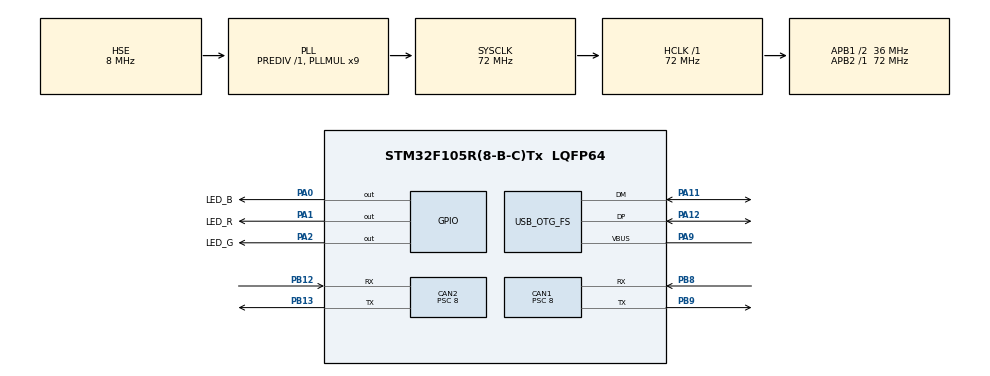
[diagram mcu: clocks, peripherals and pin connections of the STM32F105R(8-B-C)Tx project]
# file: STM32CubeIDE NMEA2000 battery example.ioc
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CAN1.BS1=CAN_BS1_15TQ
CAN1.BS2=CAN_BS2_2TQ
CAN1.CalculateBaudRate=250000
CAN1.CalculateTimeBit=4000
CAN1.CalculateTimeQuantum=222.22222222222223
CAN1.Mode=CAN_MODE_NORMAL
CAN1.Prescaler=8
CAN2.BS1=CAN_BS1_15TQ
CAN2.BS2=CAN_BS2_2TQ
CAN2.CalculateBaudRate=250000
CAN2.CalculateTimeBit=4000
CAN2.CalculateTimeQuantum=222.22222222222223
CAN2.Prescaler=8
Mcu.Family=STM32F1
Mcu.Name=STM32F105R(8-B-C)Tx
Mcu.Package=LQFP64
NVIC.CAN1_RX0_IRQn=true\:0\:0\:false\:false\:true\:true\:true\:true
NVIC.CAN1_TX_IRQn=true\:0\:0\:false\:false\:true\:true\:true\:true
NVIC.CAN2_RX1_IRQn=true\:0\:0\:false\:false\:true\:true\:true\:true
NVIC.CAN2_TX_IRQn=true\:0\:0\:false\:false\:true\:true\:true\:true
NVIC.OTG_FS_IRQn=true\:0\:0\:false\:false\:true\:true\:true\:true
NVIC.PriorityGroup=NVIC_PRIORITYGROUP_4
NVIC.TIM2_IRQn=true\:0\:0\:false\:false\:true\:true\:true\:true
PA0-WKUP.GPIO_Label=LED_B
PA0-WKUP.Signal=GPIO_Output
PA1.GPIO_Label=LED_R
PA1.Signal=GPIO_Output
PA11.Mode=Device_Only
PA11.Signal=USB_OTG_FS_DM
PA12.Mode=Device_Only
PA12.Signal=USB_OTG_FS_DP
PA13.Mode=Trace_Asynchronous_SW
PA13.Signal=SYS_JTMS-SWDIO
PA14.Mode=Trace_Asynchronous_SW
PA14.Signal=SYS_JTCK-SWCLK
PA2.GPIO_Label=LED_G
PA2.Signal=GPIO_Output
PA9.Mode=Activate_VBUS
PA9.Signal=USB_OTG_FS_VBUS
PB12.Mode=CAN_Activate
PB12.Signal=CAN2_RX
PB13.Mode=CAN_Activate
PB13.Signal=CAN2_TX
PB3.Mode=Trace_Asynchronous_SW
PB3.Signal=SYS_TRACESWO
PB8.Mode=CAN_Activate
PB8.Signal=CAN1_RX
PB9.Mode=CAN_Activate
PB9.Signal=CAN1_TX
PD0-OSC_IN.Mode=HSE-External-Oscillator
PD0-OSC_IN.Signal=RCC_OSC_IN
PD1-OSC_OUT.Mode=HSE-External-Oscillator
PD1-OSC_OUT.Signal=RCC_OSC_OUT
ProjectManager.HeapSize=0x200
ProjectManager.StackSize=0x400
ProjectManager.TargetToolchain=STM32CubeIDE
RCC.ADCPresc=RCC_ADCPCLK2_DIV6
RCC.AHBFreq_Value=72000000
RCC.APB1CLKDivider=RCC_HCLK_DIV2
RCC.APB1Freq_Value=36000000
RCC.APB1TimFreq_Value=72000000
RCC.APB2Freq_Value=72000000
RCC.APB2TimFreq_Value=72000000
RCC.HCLKFreq_Value=72000000
RCC.PLLMUL=RCC_PLL_MUL9
RCC.PLLSourceVirtual=RCC_PLLSOURCE_HSE
RCC.SYSCLKFreq_VALUE=72000000
RCC.SYSCLKSource=RCC_SYSCLKSOURCE_PLLCLK
RCC.USBFreq_Value=48000000
TIM2.Period=1000-1
TIM2.Prescaler=72-1
TIM2.TIM_MasterOutputTrigger=TIM_TRGO_UPDATE
TIM2.TIM_MasterSlaveMode=TIM_MASTERSLAVEMODE_ENABLE
TIM5.AutoReloadPreload=TIM_AUTORELOAD_PRELOAD_ENABLE
TIM5.Period=720-1
USB_DEVICE.CLASS_NAME_FS=CDC
USB_DEVICE.VirtualMode=Cdc
USB_DEVICE.VirtualModeFS=Cdc_FS
USB_OTG_FS.VirtualMode=Device_Only
VP_TIM2_VS_ClockSourceINT.Mode=Internal
VP_TIM5_VS_ClockSourceINT.Mode=Internal
VP_USB_DEVICE_VS_USB_DEVICE_CDC_FS.Mode=CDC_FS
board=custom

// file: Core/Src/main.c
/* USER CODE BEGIN Header */
/**
  ******************************************************************************
  * @file           : main.c
  * @brief          : Main program body
  ******************************************************************************
  * @attention
  *
  * <h2><center>&copy; Copyright (c) 2022 STMicroelectronics.
  * All rights reserved.</center></h2>
  *
  * This software component is licensed by ST under BSD 3-Clause license,
  * the "License"; You may not use this file except in compliance with the
  * License. You may obtain a copy of the License at:
  *                        opensource.org/licenses/BSD-3-Clause
  *
  ******************************************************************************
  */
/* USER CODE END Header */
#include "main.h"
#include "usb_device.h"

/* USER CODE BEGIN Includes */
#include "cpp_link.hpp"
/* USER CODE END Includes */

CAN_HandleTypeDef hcan1;
CAN_HandleTypeDef hcan2;

TIM_HandleTypeDef htim2;
TIM_HandleTypeDef htim5;

void SystemClock_Config(void);
static void MX_GPIO_Init(void);
static void MX_CAN1_Init(void);
static void MX_CAN2_Init(void);
static void MX_TIM2_Init(void);
static void MX_TIM5_Init(void);

int main(void)
{

  /* MCU Configuration--------------------------------------------------------*/

  /* Reset of all peripherals, Initializes the Flash interface and the Systick. */
  HAL_Init();

  /* Configure the system clock */
  SystemClock_Config();

  /* Initialize all configured peripherals */
  /* Initialize all configured peripherals */
  MX_GPIO_Init();
  MX_CAN1_Init();
  MX_CAN2_Init();
  MX_TIM2_Init();
  MX_USB_DEVICE_Init();
  MX_TIM5_Init();

  /* Infinite loop */
  /* USER CODE BEGIN WHILE */
  cpp_link();
  // we never exit cpp_link()!!!!
  // while (1) should be empty

  while (1)
  {

    /* USER CODE END WHILE */

  }
}

void SystemClock_Config(void)
{
  RCC_OscInitTypeDef RCC_OscInitStruct = {0};
  RCC_ClkInitTypeDef RCC_ClkInitStruct = {0};
  RCC_PeriphCLKInitTypeDef PeriphClkInit = {0};

  /** Initializes the RCC Oscillators according to the specified parameters
  * in the RCC_OscInitTypeDef structure.
  */
  RCC_OscInitStruct.OscillatorType = RCC_OSCILLATORTYPE_HSE;
  RCC_OscInitStruct.HSEState = RCC_HSE_ON;
  RCC_OscInitStruct.HSEPredivValue = RCC_HSE_PREDIV_DIV1;
  RCC_OscInitStruct.HSIState = RCC_HSI_ON;
  RCC_OscInitStruct.Prediv1Source = RCC_PREDIV1_SOURCE_HSE;
  RCC_OscInitStruct.PLL.PLLState = RCC_PLL_ON;
  RCC_OscInitStruct.PLL.PLLSource = RCC_PLLSOURCE_HSE;
  RCC_OscInitStruct.PLL.PLLMUL = RCC_PLL_MUL9;
  RCC_OscInitStruct.PLL2.PLL2State = RCC_PLL_NONE;
  if (HAL_RCC_OscConfig(&RCC_OscInitStruct) != HAL_OK)
  {
    Error_Handler();
  }

  /** Initializes the CPU, AHB and APB buses clocks
  */
  RCC_ClkInitStruct.ClockType = RCC_CLOCKTYPE_HCLK|RCC_CLOCKTYPE_SYSCLK
                              |RCC_CLOCKTYPE_PCLK1|RCC_CLOCKTYPE_PCLK2;
  RCC_ClkInitStruct.SYSCLKSource = RCC_SYSCLKSOURCE_PLLCLK;
  RCC_ClkInitStruct.AHBCLKDivider = RCC_SYSCLK_DIV1;
  RCC_ClkInitStruct.APB1CLKDivider = RCC_HCLK_DIV2;
  RCC_ClkInitStruct.APB2CLKDivider = RCC_HCLK_DIV1;

  if (HAL_RCC_ClockConfig(&RCC_ClkInitStruct, FLASH_LATENCY_2) != HAL_OK)
  {
    Error_Handler();
  }
  PeriphClkInit.PeriphClockSelection = RCC_PERIPHCLK_USB;
  PeriphClkInit.UsbClockSelection = RCC_USBCLKSOURCE_PLL_DIV3;
  if (HAL_RCCEx_PeriphCLKConfig(&PeriphClkInit) != HAL_OK)
  {
    Error_Handler();
  }

  /** Configure the Systick interrupt time
  */
  __HAL_RCC_PLLI2S_ENABLE();
}

static void MX_CAN1_Init(void)
{

  hcan1.Instance = CAN1;
  hcan1.Init.Prescaler = 8;
  hcan1.Init.Mode = CAN_MODE_NORMAL;
  hcan1.Init.SyncJumpWidth = CAN_SJW_1TQ;
  hcan1.Init.TimeSeg1 = CAN_BS1_15TQ;
  hcan1.Init.TimeSeg2 = CAN_BS2_2TQ;
  hcan1.Init.TimeTriggeredMode = DISABLE;
  hcan1.Init.AutoBusOff = DISABLE;
  hcan1.Init.AutoWakeUp = DISABLE;
  hcan1.Init.AutoRetransmission = DISABLE;
  hcan1.Init.ReceiveFifoLocked = DISABLE;
  hcan1.Init.TransmitFifoPriority = DISABLE;
  if (HAL_CAN_Init(&hcan1) != HAL_OK)
  {
    Error_Handler();
  }

}

static void MX_CAN2_Init(void)
{

  hcan2.Instance = CAN2;
  hcan2.Init.Prescaler = 4;
  hcan2.Init.Mode = CAN_MODE_NORMAL;
  hcan2.Init.SyncJumpWidth = CAN_SJW_1TQ;
  hcan2.Init.TimeSeg1 = CAN_BS1_15TQ;
  hcan2.Init.TimeSeg2 = CAN_BS2_2TQ;
  hcan2.Init.TimeTriggeredMode = DISABLE;
  hcan2.Init.AutoBusOff = DISABLE;
  hcan2.Init.AutoWakeUp = DISABLE;
  hcan2.Init.AutoRetransmission = DISABLE;
  hcan2.Init.ReceiveFifoLocked = DISABLE;
  hcan2.Init.TransmitFifoPriority = DISABLE;
  if (HAL_CAN_Init(&hcan2) != HAL_OK)
  {
    Error_Handler();
  }

}

static void MX_TIM2_Init(void)
{

  TIM_ClockConfigTypeDef sClockSourceConfig = {0};
  TIM_MasterConfigTypeDef sMasterConfig = {0};

  htim2.Instance = TIM2;
  htim2.Init.Prescaler = 72-1;
  htim2.Init.CounterMode = TIM_COUNTERMODE_UP;
  htim2.Init.Period = 1000-1;
  htim2.Init.ClockDivision = TIM_CLOCKDIVISION_DIV1;
  htim2.Init.AutoReloadPreload = TIM_AUTORELOAD_PRELOAD_DISABLE;
  if (HAL_TIM_Base_Init(&htim2) != HAL_OK)
  {
    Error_Handler();
  }
  sClockSourceConfig.ClockSource = TIM_CLOCKSOURCE_INTERNAL;
  if (HAL_TIM_ConfigClockSource(&htim2, &sClockSourceConfig) != HAL_OK)
  {
    Error_Handler();
  }
  sMasterConfig.MasterOutputTrigger = TIM_TRGO_UPDATE;
  sMasterConfig.MasterSlaveMode = TIM_MASTERSLAVEMODE_ENABLE;
  if (HAL_TIMEx_MasterConfigSynchronization(&htim2, &sMasterConfig) != HAL_OK)
  {
    Error_Handler();
  }

}

static void MX_TIM5_Init(void)
{

  TIM_ClockConfigTypeDef sClockSourceConfig = {0};
  TIM_MasterConfigTypeDef sMasterConfig = {0};

  htim5.Instance = TIM5;
  htim5.Init.Prescaler = 0;
  htim5.Init.CounterMode = TIM_COUNTERMODE_UP;
  htim5.Init.Period = 720-1;
  htim5.Init.ClockDivision = TIM_CLOCKDIVISION_DIV1;
  htim5.Init.AutoReloadPreload = TIM_AUTORELOAD_PRELOAD_ENABLE;
  if (HAL_TIM_Base_Init(&htim5) != HAL_OK)
  {
    Error_Handler();
  }
  sClockSourceConfig.ClockSource = TIM_CLOCKSOURCE_INTERNAL;
  if (HAL_TIM_ConfigClockSource(&htim5, &sClockSourceConfig) != HAL_OK)
  {
    Error_Handler();
  }
  sMasterConfig.MasterOutputTrigger = TIM_TRGO_RESET;
  sMasterConfig.MasterSlaveMode = TIM_MASTERSLAVEMODE_DISABLE;
  if (HAL_TIMEx_MasterConfigSynchronization(&htim5, &sMasterConfig) != HAL_OK)
  {
    Error_Handler();
  }

}

static void MX_GPIO_Init(void)
{
  GPIO_InitTypeDef GPIO_InitStruct = {0};

  /* GPIO Ports Clock Enable */
  __HAL_RCC_GPIOD_CLK_ENABLE();
  __HAL_RCC_GPIOA_CLK_ENABLE();
  __HAL_RCC_GPIOB_CLK_ENABLE();

  /*Configure GPIO pin Output Level */
  HAL_GPIO_WritePin(GPIOA, LED_B_Pin|LED_R_Pin|LED_G_Pin, GPIO_PIN_RESET);

  /*Configure GPIO pins : LED_B_Pin LED_R_Pin LED_G_Pin */
  GPIO_InitStruct.Pin = LED_B_Pin|LED_R_Pin|LED_G_Pin;
  GPIO_InitStruct.Mode = GPIO_MODE_OUTPUT_PP;
  GPIO_InitStruct.Pull = GPIO_NOPULL;
  GPIO_InitStruct.Speed = GPIO_SPEED_FREQ_LOW;
  HAL_GPIO_Init(GPIOA, &GPIO_InitStruct);

}

void Error_Handler(void)
{
  __disable_irq();
  while (1)
  {
  }
}
